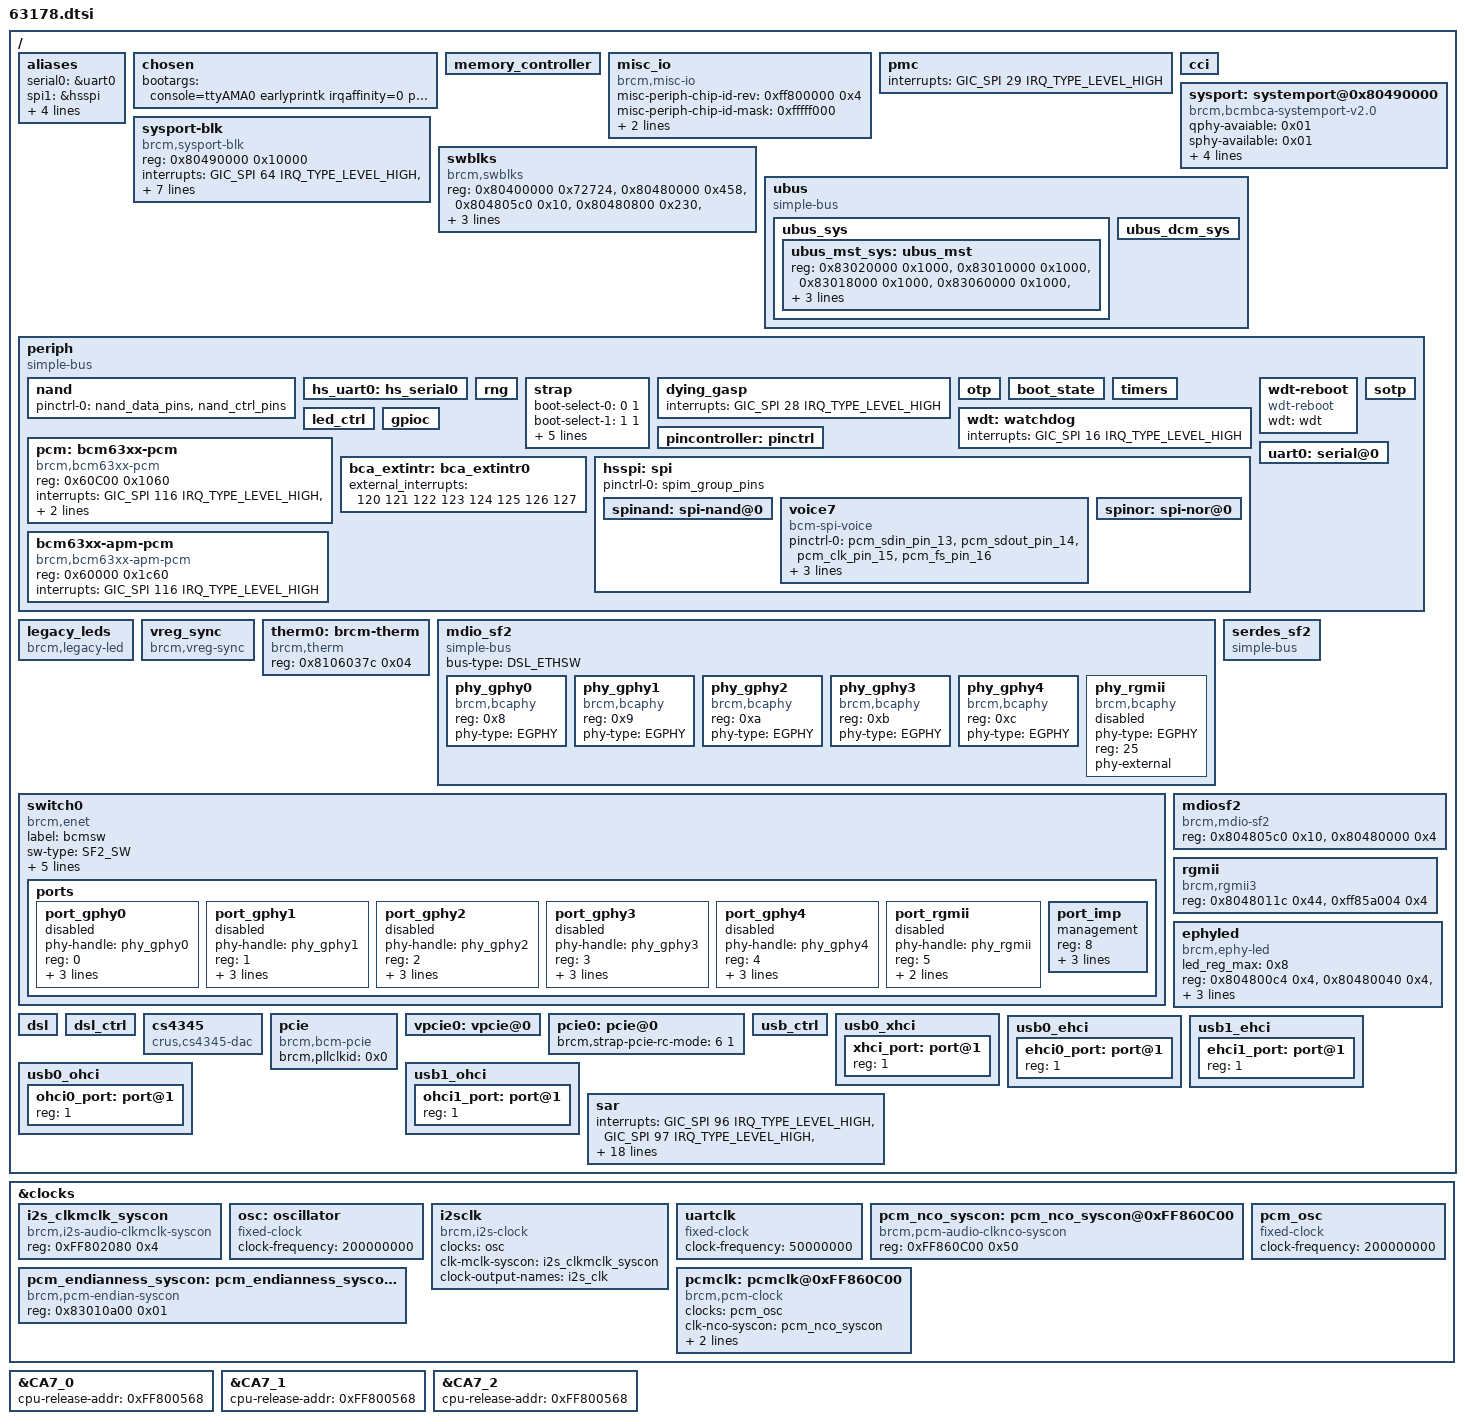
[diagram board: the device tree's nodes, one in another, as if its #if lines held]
/dts-v1/;

#define PMU_CORE0_SPI                   7
#define PMU_CORE1_SPI                   8
#define PMU_CORE2_SPI                   9


#include "linux_autoconf.h"

/* bootstrap reserved memory */
#include "../boot_rsvdmem.dtsi"

/ {
        /* arch */
	#define MODEL "Broadcom BCM963178"
	#define COMPATIBLE "brcm,bcm963178"
	#include "../ip/bcm_cortexA7_tri.dtsi"

	#define PERIPH_CLK		200000000
	#define HS_SPI_PLL_CLK	200000000
	#include "../ip/bcm_clocks.dtsi"

	/* broadcom memory reservations */
	#include "../bcm_rsvdmem.dtsi"

	aliases {
		serial0 = &uart0;
		spi1 = &hsspi; /* 0 = legacy, 1 = high speed */
		spinand0 = &spinand;
		nand0 = &nand;
		spinor0 = &spinor;
		hs_serial0  = &hs_uart0;
	};
	chosen {
		bootargs = "console=ttyAMA0 earlyprintk irqaffinity=0 pci=pcie_bus_safe isolcpus=2 rootwait rng_core.default_quality=1024";
        };

	/* memc */
	memory_controller {
		#define BP_DDR_SUPPORT_VTT                  1
		#define BP_DDR_SUPPORT_VTT_DIS_PASVTERM     0
		#define BP_DDR_63178_DEFAULT                BP_DDR_VTT_DIS_NOTERM

		#define MEMC_REG_NAMES	"memc-int-clear-reg",	\
					"memc-int-mask-clear-reg",\
					"phyctl_idle_pad_ctl",	\
					"phyctl_idle_pad_en0",	\
					"phyctl_idle_pad_en1",	\
					"phybl0_idle_pad_ctl",	\
					"phybl1_idle_pad_ctl",	\
					"phyctl_clock_idle",	\
					"phybl0_clock_idle",	\
					"phybl1_clock_idle",	\
					"auto_self_refresh",	\
					"glb_gcfg"

		#define MEMC_REG	<0x80180E08 4>,		\
					<0x80180E14 4>,		\
					<0x801a002c 4>,		\
					<0x801a0030 4>,		\
					<0x801a0034 4>,		\
					<0x801a04ac 4>,		\
					<0x801a06ac 4>,		\
					<0x801a0200 4>,		\
					<0x801a04d4 4>,		\
					<0x801a06d4 4>,		\
					<0x8018025c 4>,		\
					<0x80180004 4>

		#define MEMC_CPU_INT_LINE		19

		#include "../ip/memc.dtsi"
	};

	misc_io {
		compatible = "brcm,misc-io";
		misc-periph-chip-id-rev = <0xff800000 0x4>;
		misc-periph-chip-id-mask = <0xfffff000>;
		misc-periph-chip-id-shift = <12>;
		misc-periph-chip-rev-mask = <0xfff>;
	};

	/* PMC */
	pmc: pmc {
		#define PMC_REG_OFFSET              0x80301018
		#define PMC_REG_SIZE                0x5080
		#define PROCMON_REG_OFFSET          0x80320000
		#define PROCMON_REG_SIZE            0x240
		#define MAESTRO_REG_OFFSET          0x80300400
		#define MAESTRO_REG_SIZE            0x5d0
		#define MAESTRO_DTCM_REG_OFFSET     0x80380000
		#define MAESTRO_DTCM_REG_SIZE       0x1000
		#include "../ip/bcm_pmc_3_2.dtsi"
		interrupt-names = "pmc-temp-irq";
		interrupts = <GIC_SPI 29 IRQ_TYPE_LEVEL_HIGH>;
	};

	cci: cci {
		#define CCI_OFFSET					0x81100000 
		#define CCI_SIZE					0x8000
		#define SLAVEINTF_CPU_NUM			1
		#include "../ip/bcm_arm_cci500.dtsi"
	};

	sysport: systemport@0x80490000 {
		compatible = "brcm,bcmbca-systemport-v2.0";
		qphy-avaiable=<0x01>;
		sphy-available=<0x01>;
		reg-names = "systemport-rbuf-base", "systemport-rdma-base",
				"systemport-tdma-base",
				"systemport-gib-base",
				"systemport-umac-base",
				"systemport-topctrl-base";
		reg =		<0x80490400 0x14>,
				<0x80492000 0x1060>,
				<0x80494000 0x650>,
				<0x80498000 0x10>,
				<0x00000000 0x00>,  
				<0x80490000 0x10>;
		ethsw = <&switch0>;
	};

	sysport-blk {
		compatible = "brcm,sysport-blk";
		reg-names = "sysport-base";
		reg = <0x80490000 0x10000>;
		interrupt-names = "sysport-irq-0",
                                  "sysport-irq-1",
                                  "sysport-irq-2",
                                  "sysport-irq-3",
                                  "sysport-irq-4",
                                  "sysport-irq-5",
                                  "sysport-irq-6",
                                  "sysport-irq-7";
		interrupts = <GIC_SPI 64 IRQ_TYPE_LEVEL_HIGH>,
                             <GIC_SPI 65 IRQ_TYPE_LEVEL_HIGH>,
                             <GIC_SPI 66 IRQ_TYPE_LEVEL_HIGH>,
                             <GIC_SPI 67 IRQ_TYPE_LEVEL_HIGH>,
                             <GIC_SPI 68 IRQ_TYPE_LEVEL_HIGH>,
                             <GIC_SPI 69 IRQ_TYPE_LEVEL_HIGH>,
                             <GIC_SPI 70 IRQ_TYPE_LEVEL_HIGH>,
                             <GIC_SPI 71 IRQ_TYPE_LEVEL_HIGH>;
	};

	swblks {
		compatible = "brcm,swblks";
		reg-names = "switchcore-base",
			"switchreg-base",
			"switchmdio-base",
			"switchacb-base",
			"qphy-ctrl",
			"sphy-ctrl",
			"phy-test-ctrl";

		reg = <0x80400000 0x72724>,
			<0x80480000 0x458>,
			<0x804805c0 0x10>,
			<0x80480800 0x230>,
			<0x8048001c 0x04>,
			<0x80480024 0x04>,
			<0x80480018 0x04>;
		phy_base = <0x8>;
	};

	/* UBUS */
	ubus: ubus {
		compatible = "simple-bus";
		#address-cells = <1>;
		#size-cells = <1>;
		ranges;

		ubus_sys: ubus_sys {
			#address-cells = <1>;
			#size-cells = <1>;
			#define UBUS_SYSTOP_OFFSET         0x83000000
			#define UBUS_SYSTOP_SIZE           0x80
			#define UBUS_REGISTRATION_OFFSET   0x83000200
			#define UBUS_REGISTRATION_SIZE     0x80
			#define UBUS_COHERENCY_PORT_OFFSET 0x810A0400
			#define UBUS_COHERENCY_PORT_SIZE   0x400
			#define UBUS_MODULE_XRDP           0x0
			#include "../ip/bcm_ubus4.dtsi"
			ubus_mst_sys: ubus_mst {
				reg-names = "BIU", "PER", "USB", "DSL",
					"DSLCPU", "PCIE0", "PMC", "SWH",
					"WIFI0";
				reg = <0x83020000 0x1000>,
					<0x83010000 0x1000>,
					<0x83018000 0x1000>,
					<0x83060000 0x1000>,
					<0x83068000 0x1000>,
					<0x83030000 0x1000>,
					<0x83028000 0x1000>,
					<0x83038000 0x1000>,
					<0x83050000 0x1000>;
			};
		};

		ubus_dcm_sys: ubus_dcm_sys {
			#define UBUS_DCM_CLK_OFFSET  0x83000080
			#define UBUS_DCM_CLK_SIZE    0x80
			#define UBUS_MODULE_XRDP     0x0
			#include "../ip/bcm_ubus4_dcm.dtsi"
		};
	};
	
	periph {
		compatible = "simple-bus";
		#address-cells = <1>;
		#size-cells = <1>;
		ranges = <0 0xff800000 0x7fffff>;

		nand: nand {
			pinctrl-0 = <&nand_data_pins &nand_ctrl_pins>;
			pinctrl-names = "default";	
			#define NAND_CTRL_OFFSET		0x1800
			#define NAND_CTRL_SIZE			0x400
			#define NAND_INTR_OFFSET		0x2000
			#define NAND_INTR_SIZE			0x10
			#define NAND_CACHE_OFFSET		0x1C00
			#define NAND_CACHE_SIZE			0x200
			#include "../ip/bcm_nand7_1.dtsi"
		};

		hs_uart0: hs_serial0 {
			#define UART_OFFSET			0x10400
			#define UART_SIZE			0x1E0
			#define UART_SPI			34
			#include "../ip/bcm_hs_uart.dtsi"
		};

		/* RNG */
		rng: rng {
			#define RNG200_OFFSET                   0xb80
			#define RNG200_SIZE                     0x30
			#include "../ip/bcm_rng200.dtsi"
		};

		strap: strap {
			#define STRAP_REG_OFFSET            0x2600
			#define STRAP_REG_SIZE              0x4
			#include "../ip/bcm_strap.dtsi"
			boot-select-0=<0 1>;
			boot-select-1=<1 1>;
			boot-select-2=<2 1>;
			boot-select-3=<3 1>;
			boot-select-4=<4 1>;
			boot-select-5=<5 1>;
			bootrom-boot=<11 1>;
		};

		dying_gasp: dying_gasp {
			#define DG_IRQ_MASK_REG_OFFSET	0x5A024
			#define DG_IRQ_MASK_REG_SIZE	0x4
			#define DG_UART_DR_OFFSET	0x12000
			#define DG_UART_DR_SIZE		0x4
			#include "../ip/bcm_dgasp_pmc.dtsi"
			interrupts = <GIC_SPI 28 IRQ_TYPE_LEVEL_HIGH>;
		};

		otp: otp {
			#define OTP_REG_OFFSET            0x2800 
			#define OTP_REG_SIZE              0x78
			#include "../ip/bcm_otp.dtsi"
		};

		/* boot state */
		boot_state: boot_state {
			#define RESET_REASON_OFFSET  0x2628
			#define RESET_REASON_SIZE    0x4
			#define RESET_STATUS_OFFSET  0x5a03c
			#define RESET_STATUS_SIZE    0x4
			#include "../ip/bcm_boot_state_v2.dtsi"
		};

		/* periph timers */
		timers: timers {
			#define TIMERS_OFFSET		0x400
			#define TIMERS__SIZE		0x48
			#define TIMER0_SPI			11
			#define TIMER1_SPI			12
			#define TIMER2_SPI			13
			#define TIMER3_SPI			14
			#include "../ip/bcm_timer.dtsi"
		};

		/* watchdog */
		wdt: watchdog {
			#define WATCHDOG_OFFSET			0x480
			#define WATCHDOG_SIZE			0x10
			#define WATCHDOG_TIMEOUT		80
			#include "../ip/bcm_wdt.dtsi"
			interrupts = <GIC_SPI 16 IRQ_TYPE_LEVEL_HIGH>;
		};
		/* watchdog reboot */
		wdt-reboot {
			compatible = "wdt-reboot";
			wdt = <&wdt>;
		};

		/* sotp */
		sotp {
			#define SOTP_OFFSET			0xc00
			#define SOTP_SIZE			0x84
			#include "../ip/bcm_sotp.dtsi"
		};
		
		/* Led Controller */
		led_ctrl: led_ctrl {
			#define CLED_GLBL_CTRL_OFFSET           0x3000
			#define CLED_GLBL_CTRL_SIZE             0x4
			#define CLED_HW_EN_OFFSET               0x3004
			#define CLED_HW_EN_SIZE                 0x4
			#define CLED_SER_SHIFT_OFFSET           0x3008
			#define CLED_SER_SHIFT_SIZE             0x4
			#define CLED_HW_POLARITY_OFFSET         0x300c
			#define CLED_HW_POLARITY_SIZE           0x4
			#define CLED_SW_SET_OFFSET              0x3010
			#define CLED_SW_SET_SIZE                0x4
			#define CLED_SW_POLARITY_OFFSET         0x3014
			#define CLED_SW_POLARITY_SIZE           0x4
			#define CLED_CH_ACTIVATE_OFFSET         0x301c
			#define CLED_CH_ACTIVATE_SIZE           0x4
			#define CLED_XX_CONFIG_OFFSET           0x3020
			#define CLED_XX_CONFIG_SIZE             0x200
			#define CLED_SERIAL_POLARITY_OFFSET     0x3454
			#define CLED_SERIAL_POLARITY_SIZE       0x4
			#define CLED_PARALLEL_POLARITY_OFFSET   0x3018
			#define CLED_PARALLEL_POLARITY_SIZE     0x4
			#define MAX_SUPPORTED_LEDS              32

			status = "okay";
			#include "../ip/bcm_cled_legacy_ctrl.dtsi"
			#include "63178_leds.dtsi"
		};

		pcm: bcm63xx-pcm {
			compatible = "brcm,bcm63xx-pcm";
			reg = <0x60C00 0x1060>;
			interrupts = <GIC_SPI 116 IRQ_TYPE_LEVEL_HIGH>,<GIC_SPI 117 IRQ_TYPE_LEVEL_HIGH>;
			clocks = <&pcmclk>, <&pcm_osc>;
			clock-names = "pcmclk","pcmosc"; 
		};
		/* pinctrl */
		pincontroller: pinctrl {
			#define PINCTRL_OFFSET       0x554
			#define PINCTRL_SIZE         0xc
			#define PINCTRL_NUM_PINS     88
			#define PINCTRL_NUM_FUNC     8
			#define PINCTRL_GPIO_FUNC    5
			#include "../ip/bcm_bca_pinctrl.dtsi"
			#include "63178_pinctrl.dtsi"
		};
		/* gpio */
		gpioc: gpioc {
			#define GPIO_DIR_OFFSET      0x500
			#define GPIO_DIR_SIZE        0x20
			#define GPIO_DATA_OFFSET     0x520
			#define GPIO_DATA_SIZE       0x20
			#define NUM_OF_GPIOS         88
			#include "../ip/bcm_bca_gpio.dtsi"
		};

		/* external interrups */
		bca_extintr: bca_extintr0 {
			#define EXTINTR_OFFSET       0x4
			#define EXTINTR_SIZE         0x48
			#define MAX_EXT_INTR         8
			#include "../ip/bcm_bca_extintr.dtsi"
			external_interrupts = <120 121 122 123 124 125 126 127>;
		};
		
		/* UART 1*/
		uart0: serial@0 {
			#define UART_OFFSET			0x12000
			#define UART_SIZE			0x1000
			#define UART_SPI			32
			#define UART_CLK_LABEL			refclk50mhz
			#define UART_CLK			50000000
			#include "../ip/bcm_arm_uart.dtsi"
		};
		/* HS SPI */
		hsspi: spi {
			pinctrl-0 = <&spim_group_pins>;
			pinctrl-names = "default";
			#define HS_SPI_OFFSET			0x1000
			#define HS_SPI_SIZE			0x600
			#define HS_SPI_MAX_FREQ			100000000
			/* #define HS_SPIM_SPI			36 */
			#include "../ip/bcm_hsspi.dtsi"
			spinand: spi-nand@0 {
				#define SPINAND_MAX_FREQ	100000000
				#include "../ip/bcm_spinand.dtsi"
			};
			voice7 {
				pinctrl-0 = <&pcm_sdin_pin_13 &pcm_sdout_pin_14 &pcm_clk_pin_15 &pcm_fs_pin_16>;
				pinctrl-names = "default";
				compatible = "bcm-spi-voice";
				reg = <7>; /* chip select 7 */
				spi-index = <7>;/* ZSI/ISI header position index */
				spi-max-frequency = <1024000>;
			};	
			spinor: spi-nor@0 {
				#define SPINOR_MAX_FREQ	50000000
				#include "../ip/bcm_spinor.dtsi"
			};
		};

		bcm63xx-apm-pcm {
			compatible = "brcm,bcm63xx-apm-pcm";
			reg = <0x60000 0x1c60>;
			interrupts = <GIC_SPI 116 IRQ_TYPE_LEVEL_HIGH>;
		};		

	};

	legacy_leds: legacy_leds {
		compatible = "brcm,legacy-led";
	};

	vreg_sync: vreg_sync {
		compatible = "brcm,vreg-sync";
	};

	therm0: brcm-therm {
		compatible = "brcm,therm";
		reg-names="bac_cpu_therm_temp";
		reg = <0x8106037c 0x04>;
		status = "okay";
	};

	mdio_sf2: mdio_sf2 {
		compatible = "simple-bus";
		bus-type = "DSL_ETHSW";
		#address-cells = <1>;
		#size-cells = <0>;

		/* Port PHY mapping:
                port_imp -8#0- port_gphy0 <--> phy_gphy0
                          # 1- port_gphy1 <--> phy_gphy1
                          # 2- port_gphy2 <--> phy_gphy2
                          # 3- port_gphy3 <--> phy_gphy3
                          # 4- port_gphy4 <--> phy_gphy4
                          ##5- port_rgmii <--> phy_rgmii
		 */
		phy_gphy0:phy_gphy0 {
			compatible = "brcm,bcaphy";
			reg = <0x8>;
			phy-type = "EGPHY";
		};
		phy_gphy1:phy_gphy1 {
			compatible = "brcm,bcaphy";
			reg = <0x9>;
			phy-type = "EGPHY";
		};
		phy_gphy2:phy_gphy2 {
			compatible = "brcm,bcaphy";
			reg = <0xa>;
			phy-type = "EGPHY";
		};
		phy_gphy3:phy_gphy3 {
			compatible = "brcm,bcaphy";
			reg = <0xb>;
			phy-type = "EGPHY";
		};
		phy_gphy4:phy_gphy4 {
			compatible = "brcm,bcaphy";
			reg = <0xc>;
			phy-type = "EGPHY";
		};
		phy_rgmii:phy_rgmii {
			compatible = "brcm,bcaphy";
			phy-type = "EGPHY";
			reg = <25>;
			status = "disabled";
			phy-external;
		};
	};

	serdes_sf2: serdes_sf2 {
		compatible = "simple-bus";
	};

	switch0:switch0 {
		compatible = "brcm,enet", "brcm,bcmbca-sf2";
		label = "bcmsw";
		sw-type = "SF2_SW";

		phy_base = <0x8>;
		phy_wkard_timeout = <25000>;
		reg-names = "switchcore-base",
					"switchreg-base",
					"switchmdio-base",
					"qphy-ctrl",
					"sphy-ctrl",
					"phy-test-ctrl";

		reg = <0x80400000 0x72724>,
			<0x80480000 0x458>,
			<0x804805c0 0x10>,
			<0x8048001c 0x04>,
			<0x80480024 0x04>,
			<0x80480018 0x04>;

		ports {
			#address-cells = <1>;
			#size-cells = <0>;
			port_gphy0 {
				phy-handle = <&phy_gphy0>;
				reg = <0>;
				mac-type = "SF2MAC";
				phy-mode = "gmii";
				gmii-direct;
				status = "disabled";
			};
			port_gphy1 {
				phy-handle = <&phy_gphy1>;
				reg = <1>;
				mac-type = "SF2MAC";
				phy-mode = "gmii";
				gmii-direct;
				status = "disabled";
			};
			port_gphy2 {
				phy-handle = <&phy_gphy2>;
				reg = <2>;
				mac-type = "SF2MAC";
				phy-mode = "gmii";
				gmii-direct;
				status = "disabled";
			};
			port_gphy3 {
				phy-handle = <&phy_gphy3>;
				reg = <3>;
				mac-type = "SF2MAC";
				phy-mode = "gmii";
				gmii-direct;
				status = "disabled";
			};
			port_gphy4 {
				phy-handle = <&phy_gphy4>;
				reg = <4>;
				mac-type = "SF2MAC";
				phy-mode = "gmii";
				gmii-direct;
				status = "disabled";
			};
			port_rgmii {
				phy-handle = <&phy_rgmii>;
				reg = <5>;
				mac-type = "SF2MAC";
				phy-mode = "rgmii";
				status = "disabled";
			};
			port_imp {
				management;
				reg = <8>;
				mac-type = "SF2MAC";
				phy-mode = "gmii";
				gmii-direct;
				status = "okay";
			};
		};
	};

	mdiosf2 {
		compatible = "brcm,mdio-sf2";
		reg = <0x804805c0 0x10>,
		      <0x80480000 0x4>;
	};

	rgmii: rgmii {
		compatible = "brcm,rgmii3";
		reg = <0x8048011c  0x44>,
		      <0xff85a004  0x4>;
	};

	ephyled {
	    compatible = "brcm,ephy-led";
            led_reg_max=<0x8>;
            reg-names = "aggregate_ctrl", "led_reg_0", "led_reg_1", "led_reg_2", "led_reg_3", "led_reg_4", "led_reg_5", "led_reg_8"; 
            reg = <0x804800c4 0x4>, < 0x80480040 0x4>, < 0x8048004c 0x4>, < 0x80480058 0x4>, < 0x80480064 0x4>, < 0x80480070 0x4>, < 0x8048007c 0x4>, < 0x804800a0 0x4>;
	};

	dsl:dsl {
		#define DSL_LINE_0
		#include "../ip/bcm_dsl.dtsi"
	};

	dsl_ctrl: dsl_ctrl {
		#define DSL_PHY_OFFSET		0x80650000
		#define DSL_PHY_SIZE		0x20000
		#define DSL_LMEM_OFFSET		0x80700000
		#define DSL_LMEM_SIZE		0x90000
		#define DSL_SPI				39
		#include "../ip/bcm_dsl_ctrl.dtsi"
	};

	cs4345 {
		compatible = "crus,cs4345-dac";
	};

#if defined(CONFIG_BCM_PCIE_HCD) || defined(CONFIG_BCM_PCIE_HCD_MODULE)
	/* pcie common */
	pcie: pcie {
		compatible = "brcm,bcm-pcie";
		device_type = "cpci";
		brcm,pllclkid = <0x0>;
	};

	/* Internal WiFi Core 0 (virtual pcie with domain#0) */
	vpcie0: vpcie@0 {
		#define WIFI_COREID			0
		#define WIFI_ADDR			0x84000000
		#define WIFI_SIZE			0x01000000
		#define WIFI_DEVID			0xf6ca
		#define WIFI_CCM_SPI		44
		#define WIFI_D11MAC_SPI		46
		#define WIFI_M2MDMA_SPI		45
		#define WIFI_WDRST_SPI		47
		#include "../ip/bcm_wifi_core.dtsi"
	};

	/* pcie core 0 */
	pcie0: pcie@0 {
		#define PCIE_ID				0
		#define PCIE_DOMAIN_ID			1
		#define PCIE_SPI			43
		#define PCIE_ADDR			0x80040000
		#define PCIE_SIZE			0x0000A000
		#define PCIE_RANGE_ADDR		0xC0000000
		#define PCIE_RANGE_SIZE		0x10000000
		#include "../ip/bcm_pcie_core.dtsi"
		brcm,strap-pcie-rc-mode=<6 1>; 
	};
#endif

	/* usb */
	usb_ctrl: usb_ctrl {
		#define USB_CTRL_ADDR		0x8000c200
		#define USB_CTRL_SIZE 		0x100
		#include "../ip/bcm_usb_ctrl.dtsi"
	};

	usb0_xhci: usb0_xhci {
		#define USB_ADDR 		0x8000d000
		#define USB_SIZE		0x1000
		#define USB_IRQ			74
		#include "../ip/bcm_usb_xhci.dtsi"

		xhci_port: port@1{
			reg = <1>;
			#trigger-source-cells = <0>;
		};
	};

	usb0_ehci: usb0_ehci {
		#define USB_ADDR		0x8000c300
		#define USB_SIZE		0x100
		#define USB_IRQ			73
		#include "../ip/bcm_usb_ehci.dtsi"

 		ehci0_port: port@1{
			reg = <1>;
			#trigger-source-cells = <0>;
		};
	};

	usb1_ehci: usb1_ehci {
		#define USB_ADDR		0x8000c500
		#define USB_SIZE		0x100
		#define USB_IRQ			73
		#include "../ip/bcm_usb_ehci.dtsi"

		ehci1_port: port@1{
			reg = <1>;
			#trigger-source-cells = <0>;
		};
	};

	usb0_ohci: usb0_ohci {
		#define USB_ADDR		0x8000c400
		#define USB_SIZE		0x100
		#define USB_IRQ			72
		#include "../ip/bcm_usb_ohci.dtsi"

 		ohci0_port: port@1{
			reg = <1>;
			#trigger-source-cells = <0>;
		};
	};

	usb1_ohci: usb1_ohci {
		#define USB_ADDR		0x8000c600
		#define USB_SIZE		0x100
		#define USB_IRQ			72
		#include "../ip/bcm_usb_ohci.dtsi"

 		ohci1_port: port@1{
			reg = <1>;
			#trigger-source-cells = <0>;
		};
	};

   sar:sar {
      #define SAR_OFFSET   0x80800000
      #define SAR_SIZE     0x4000
      #define IUDMA_OFFSET 0x80806000
      #define IUDMA_SIZE   0x800
      #define TXPAF_OFFSET IUDMA_OFFSET
      #define TXPAF_SIZE   IUDMA_SIZE
      #define SAR_CLK_FREQ "300000000"
      #include "../ip/bcm_sar.dtsi"
      interrupt-names = "sar-irq-0",
                        "sar-irq-1",
                        "sar-irq-2",
                        "sar-irq-3",
                        "sar-irq-4",
                        "sar-irq-5",
                        "sar-irq-6",
                        "sar-irq-7",
                        "sar-irq-8",
                        "sar-irq-9",
                        "sar-irq-10",
                        "sar-irq-11",
                        "sar-irq-12",
                        "sar-irq-13",
                        "sar-irq-14",
                        "sar-irq-15",
                        "sar-irq-16",
                        "sar-irq-17",
                        "sar-irq-18",
                        "sar-irq-19";
      interrupts = <GIC_SPI 96 IRQ_TYPE_LEVEL_HIGH>,
                   <GIC_SPI 97 IRQ_TYPE_LEVEL_HIGH>,
                   <GIC_SPI 98 IRQ_TYPE_LEVEL_HIGH>,
                   <GIC_SPI 99 IRQ_TYPE_LEVEL_HIGH>,
                   <GIC_SPI 100 IRQ_TYPE_LEVEL_HIGH>,
                   <GIC_SPI 101 IRQ_TYPE_LEVEL_HIGH>,
                   <GIC_SPI 102 IRQ_TYPE_LEVEL_HIGH>,
                   <GIC_SPI 103 IRQ_TYPE_LEVEL_HIGH>,
                   <GIC_SPI 104 IRQ_TYPE_LEVEL_HIGH>,
                   <GIC_SPI 105 IRQ_TYPE_LEVEL_HIGH>,
                   <GIC_SPI 106 IRQ_TYPE_LEVEL_HIGH>,
                   <GIC_SPI 107 IRQ_TYPE_LEVEL_HIGH>,
                   <GIC_SPI 108 IRQ_TYPE_LEVEL_HIGH>,
                   <GIC_SPI 109 IRQ_TYPE_LEVEL_HIGH>,
                   <GIC_SPI 110 IRQ_TYPE_LEVEL_HIGH>,
                   <GIC_SPI 111 IRQ_TYPE_LEVEL_HIGH>,
                   <GIC_SPI 112 IRQ_TYPE_LEVEL_HIGH>,
                   <GIC_SPI 113 IRQ_TYPE_LEVEL_HIGH>,
                   <GIC_SPI 114 IRQ_TYPE_LEVEL_HIGH>,
                   <GIC_SPI 115 IRQ_TYPE_LEVEL_HIGH>;
   };
};

&clocks {
	#address-cells = <1>;
	#size-cells    = <1>;
	ranges;

	i2s_clkmclk_syscon: i2s_clkmclk_syscon{
		compatible        = "brcm,i2s-audio-clkmclk-syscon", "syscon";
		reg               = <0xFF802080 0x4>;
	};
	osc: oscillator {
		#clock-cells      = <0>;
		compatible        = "fixed-clock";
		clock-frequency   = <200000000>; /* xpon 200MHz output */
	};

	i2sclk: i2sclk {
		#clock-cells       = <0>;
		compatible         = "brcm,i2s-clock";
		clocks = <&osc>;
		clk-mclk-syscon    = <&i2s_clkmclk_syscon>;
		clock-output-names = "i2s_clk";
	};

	uartclk: uartclk {
		compatible = "fixed-clock";
		#clock-cells = <0>;
		clock-frequency = <50000000>;
	};
	
	pcm_nco_syscon: pcm_nco_syscon@0xFF860C00 {
		compatible = "brcm,pcm-audio-clknco-syscon", "syscon";
		reg = <0xFF860C00 0x50>; /* temp setting here. to do: size should be re-cal for only we need.*/
	};
	pcm_osc: pcm_osc {
		#clock-cells = <0>;
		compatible = "fixed-clock";
		clock-frequency = <200000000>; /* 200.00MHz fixed output */
	};

	pcm_endianness_syscon: pcm_endianness_syscon@0x83010a00 {
		compatible = "brcm,pcm-endian-syscon", "syscon";
		reg = <0x83010a00 0x01>;
	};

	pcmclk: pcmclk@0xFF860C00 {
		#clock-cells = <0>;
		compatible = "brcm,pcm-clock";
		clocks = <&pcm_osc>;
		clk-nco-syscon = <&pcm_nco_syscon>;
		pcm-endian-syscon = <&pcm_endianness_syscon>;
		clock-output-names = "pcm_clk";

	};
};

&uart0 {
	status = "okay";
};
&wdt {
	status = "okay";
};
&hsspi {
	status = "okay";
};
&spinand {
	status = "okay";
};
&spinor {
	status = "okay";
};
&rgmii {
	status = "okay";
};
&sar {
   status = "okay";
};
#if defined(CONFIG_BCM_PCIE_HCD) || defined(CONFIG_BCM_PCIE_HCD_MODULE)
&pcie0 {
	status = "okay";
};
#endif

&CA7_0 {
	cpu-release-addr = <0xFF800568>;
};

&CA7_1 {
	cpu-release-addr = <0xFF800568>;
};

&CA7_2 {
	cpu-release-addr = <0xFF800568>;
};

&dsl_ctrl {
	status = "okay";
};
